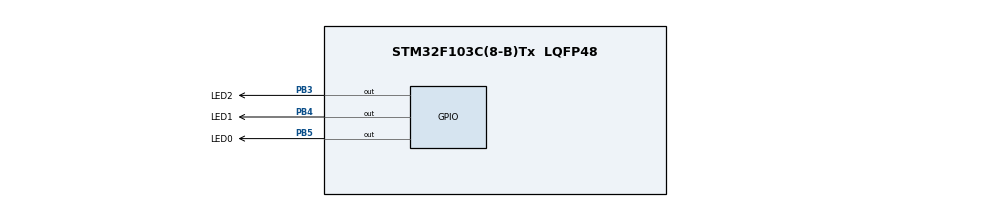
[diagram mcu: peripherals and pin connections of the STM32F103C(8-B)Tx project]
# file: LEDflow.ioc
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FREERTOS.Tasks01=LED0,24,128,led0,Default,NULL,Dynamic,NULL,NULL;LED1,8,128,led1,Default,NULL,Dynamic,NULL,NULL;LED2,8,128,led2,Default,NULL,Dynamic,NULL,NULL
Mcu.Family=STM32F1
Mcu.Name=STM32F103C(8-B)Tx
Mcu.Package=LQFP48
NVIC.PriorityGroup=NVIC_PRIORITYGROUP_4
NVIC.TIM2_IRQn=true\:15\:0\:false\:false\:true\:false\:false\:true\:true
NVIC.TimeBase=TIM2_IRQn
NVIC.TimeBaseIP=TIM2
PA13.Mode=Serial_Wire
PA13.Signal=SYS_JTMS-SWDIO
PA14.Mode=Serial_Wire
PA14.Signal=SYS_JTCK-SWCLK
PB3.GPIO_Label=LED2
PB3.GPIO_ModeDefaultOutputPP=GPIO_MODE_OUTPUT_OD
PB3.GPIO_PuPd=GPIO_NOPULL
PB3.PinState=GPIO_PIN_SET
PB3.Signal=GPIO_Output
PB4.GPIO_Label=LED1
PB4.GPIO_ModeDefaultOutputPP=GPIO_MODE_OUTPUT_OD
PB4.GPIO_PuPd=GPIO_NOPULL
PB4.PinState=GPIO_PIN_SET
PB4.Signal=GPIO_Output
PB5.GPIO_Label=LED0
PB5.GPIO_ModeDefaultOutputPP=GPIO_MODE_OUTPUT_OD
PB5.GPIO_PuPd=GPIO_NOPULL
PB5.PinState=GPIO_PIN_SET
PB5.Signal=GPIO_Output
ProjectManager.HeapSize=0x200
ProjectManager.StackSize=0x400
ProjectManager.TargetToolchain=CMake
RCC.APB1Freq_Value=8000000
RCC.APB2Freq_Value=8000000
VP_FREERTOS_VS_CMSIS_V2.Mode=CMSIS_V2
VP_SYS_VS_tim2.Mode=TIM2
board=custom

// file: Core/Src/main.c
/* USER CODE BEGIN Header */
/**
  ******************************************************************************
  * @file           : main.c
  * @brief          : Main program body
  ******************************************************************************
  * @attention
  *
  * Copyright (c) 2026 STMicroelectronics.
  * All rights reserved.
  *
  * This software is licensed under terms that can be found in the LICENSE file
  * in the root directory of this software component.
  * If no LICENSE file comes with this software, it is provided AS-IS.
  *
  ******************************************************************************
  */
/* USER CODE END Header */
#include "main.h"
#include "cmsis_os.h"
#include "gpio.h"

/* USER CODE BEGIN PD */
#define LED_FLOW_INTERVAL_MS   500U
/* USER CODE END PD */

void SystemClock_Config(void);
void MX_FREERTOS_Init(void);

int main(void)
{

  /* MCU Configuration--------------------------------------------------------*/

  /* Reset of all peripherals, Initializes the Flash interface and the Systick. */
  HAL_Init();

  /* Configure the system clock */
  SystemClock_Config();

  /* Initialize all configured peripherals */
  MX_GPIO_Init();

  /* Init scheduler */
  osKernelInitialize();  /* Call init function for freertos objects (in cmsis_os2.c) */
  MX_FREERTOS_Init();

  /* Start scheduler */
  osKernelStart();

  /* We should never get here as control is now taken by the scheduler */

  /* Infinite loop */
  while (1)
  {

  }
}

void SystemClock_Config(void)
{
  RCC_OscInitTypeDef RCC_OscInitStruct = {0};
  RCC_ClkInitTypeDef RCC_ClkInitStruct = {0};

  /** Initializes the RCC Oscillators according to the specified parameters
  * in the RCC_OscInitTypeDef structure.
  */
  RCC_OscInitStruct.OscillatorType = RCC_OSCILLATORTYPE_HSI;
  RCC_OscInitStruct.HSIState = RCC_HSI_ON;
  RCC_OscInitStruct.HSICalibrationValue = RCC_HSICALIBRATION_DEFAULT;
  RCC_OscInitStruct.PLL.PLLState = RCC_PLL_NONE;
  if (HAL_RCC_OscConfig(&RCC_OscInitStruct) != HAL_OK)
  {
    Error_Handler();
  }

  /** Initializes the CPU, AHB and APB buses clocks
  */
  RCC_ClkInitStruct.ClockType = RCC_CLOCKTYPE_HCLK|RCC_CLOCKTYPE_SYSCLK
                              |RCC_CLOCKTYPE_PCLK1|RCC_CLOCKTYPE_PCLK2;
  RCC_ClkInitStruct.SYSCLKSource = RCC_SYSCLKSOURCE_HSI;
  RCC_ClkInitStruct.AHBCLKDivider = RCC_SYSCLK_DIV1;
  RCC_ClkInitStruct.APB1CLKDivider = RCC_HCLK_DIV1;
  RCC_ClkInitStruct.APB2CLKDivider = RCC_HCLK_DIV1;

  if (HAL_RCC_ClockConfig(&RCC_ClkInitStruct, FLASH_LATENCY_0) != HAL_OK)
  {
    Error_Handler();
  }
}

void HAL_TIM_PeriodElapsedCallback(TIM_HandleTypeDef *htim)
{
  if (htim->Instance == TIM2)
  {
    HAL_IncTick();
  }
}

void Error_Handler(void)
{
  __disable_irq();
  while (1)
  {
  }
}

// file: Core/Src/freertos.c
/* USER CODE BEGIN Header */
/**
  ******************************************************************************
  * File Name          : freertos.c
  * Description        : Code for freertos applications
  ******************************************************************************
  * @attention
  *
  * Copyright (c) 2026 STMicroelectronics.
  * All rights reserved.
  *
  * This software is licensed under terms that can be found in the LICENSE file
  * in the root directory of this software component.
  * If no LICENSE file comes with this software, it is provided AS-IS.
  *
  ******************************************************************************
  */
/* USER CODE END Header */

#include "FreeRTOS.h"
#include "task.h"
#include "main.h"
#include "cmsis_os.h"

/* USER CODE BEGIN PD */
#define LED_ON_MS    500U
#define LED_OFF_MS   1000U
/* USER CODE END PD */

/* Definitions for LED0 */
osThreadId_t LED0Handle;
const osThreadAttr_t LED0_attributes = {
  .name = "LED0",
  .stack_size = 128 * 4,
  .priority = (osPriority_t) osPriorityNormal,
};
/* Definitions for LED1 */
osThreadId_t LED1Handle;
const osThreadAttr_t LED1_attributes = {
  .name = "LED1",
  .stack_size = 128 * 4,
  .priority = (osPriority_t) osPriorityLow,
};
/* Definitions for LED2 */
osThreadId_t LED2Handle;
const osThreadAttr_t LED2_attributes = {
  .name = "LED2",
  .stack_size = 128 * 4,
  .priority = (osPriority_t) osPriorityLow,
};

void led0(void *argument);
void led1(void *argument);
void led2(void *argument);

void MX_FREERTOS_Init(void); /* (MISRA C 2004 rule 8.1) */

void MX_FREERTOS_Init(void) {

  /* Create the thread(s) */
  /* creation of LED0 */
  LED0Handle = osThreadNew(led0, NULL, &LED0_attributes);

  /* creation of LED1 */
  LED1Handle = osThreadNew(led1, NULL, &LED1_attributes);

  /* creation of LED2 */
  LED2Handle = osThreadNew(led2, NULL, &LED2_attributes);

}

void led0(void *argument)
{
  /* USER CODE BEGIN led0 */
  /* Infinite loop */
  for(;;)
  {
    HAL_GPIO_WritePin(LED0_GPIO_Port, LED0_Pin, GPIO_PIN_RESET);
    osDelay(LED_ON_MS);
    HAL_GPIO_WritePin(LED0_GPIO_Port, LED0_Pin, GPIO_PIN_SET);
    osDelay(LED_OFF_MS);
  }
  /* USER CODE END led0 */
}

void led1(void *argument)
{
  /* USER CODE BEGIN led1 */
  osDelay(LED_ON_MS);   /* phase shift: LED1 follows LED0 */
  /* Infinite loop */
  for(;;)
  {
    HAL_GPIO_WritePin(LED1_GPIO_Port, LED1_Pin, GPIO_PIN_RESET);
    osDelay(LED_ON_MS);
    HAL_GPIO_WritePin(LED1_GPIO_Port, LED1_Pin, GPIO_PIN_SET);
    osDelay(LED_OFF_MS);
  }
  /* USER CODE END led1 */
}

void led2(void *argument)
{
  /* USER CODE BEGIN led2 */
  osDelay(LED_ON_MS * 2U);   /* phase shift: LED2 follows LED1 */
  /* Infinite loop */
  for(;;)
  {
    HAL_GPIO_WritePin(LED2_GPIO_Port, LED2_Pin, GPIO_PIN_RESET);
    osDelay(LED_ON_MS);
    HAL_GPIO_WritePin(LED2_GPIO_Port, LED2_Pin, GPIO_PIN_SET);
    osDelay(LED_OFF_MS);
  }
  /* USER CODE END led2 */
}
